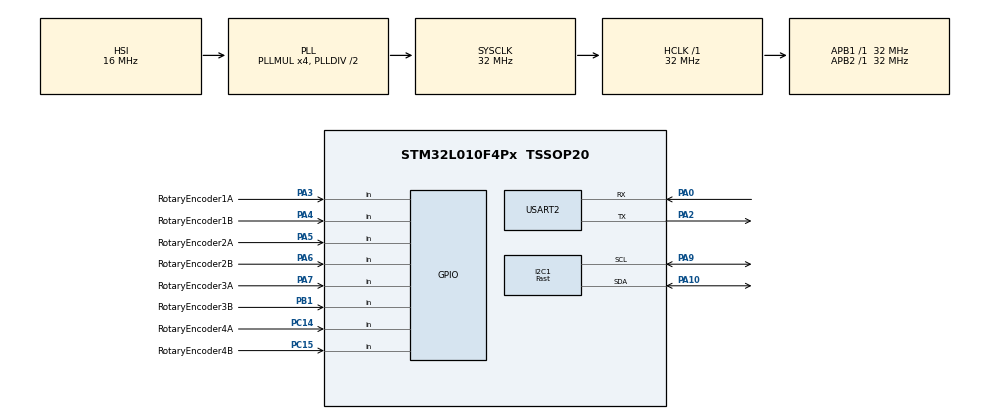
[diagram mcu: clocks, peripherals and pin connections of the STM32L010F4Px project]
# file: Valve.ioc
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Dma.Request0=USART2_RX
Dma.USART2_RX.0.Direction=DMA_PERIPH_TO_MEMORY
Dma.USART2_RX.0.Instance=DMA1_Channel3
Dma.USART2_RX.0.MemDataAlignment=DMA_MDATAALIGN_BYTE
Dma.USART2_RX.0.MemInc=DMA_MINC_ENABLE
Dma.USART2_RX.0.Mode=DMA_CIRCULAR
Dma.USART2_RX.0.PeriphDataAlignment=DMA_PDATAALIGN_BYTE
Dma.USART2_RX.0.PeriphInc=DMA_PINC_DISABLE
Dma.USART2_RX.0.Priority=DMA_PRIORITY_LOW
I2C1.I2C_Speed_Mode=I2C_Fast
I2C1.Timing=0x00300F38
Mcu.Family=STM32L0
Mcu.Name=STM32L010F4Px
Mcu.Package=TSSOP20
NVIC.DMA1_Channel2_3_IRQn=true\:0\:0\:false\:false\:true\:false\:true
NVIC.TIM2_IRQn=true\:0\:0\:false\:false\:true\:true\:true
PA0-CK_IN.Mode=Asynchronous
PA0-CK_IN.Signal=USART2_RX
PA10.Mode=I2C
PA10.Signal=I2C1_SDA
PA13.Mode=Serial_Wire
PA13.Signal=SYS_SWDIO
PA14.Mode=Serial_Wire
PA14.Signal=SYS_SWCLK
PA2.Mode=Asynchronous
PA2.Signal=USART2_TX
PA3.GPIO_Label=RotaryEncoder1A
PA3.GPIO_PuPd=GPIO_PULLUP
PA3.Signal=GPIO_Input
PA4.GPIO_Label=RotaryEncoder1B
PA4.GPIO_PuPd=GPIO_PULLUP
PA4.Signal=GPIO_Input
PA5.GPIO_Label=RotaryEncoder2A
PA5.GPIO_PuPd=GPIO_PULLUP
PA5.Signal=GPIO_Input
PA6.GPIO_Label=RotaryEncoder2B
PA6.GPIO_PuPd=GPIO_PULLUP
PA6.Signal=GPIO_Input
PA7.GPIO_Label=RotaryEncoder3A
PA7.GPIO_PuPd=GPIO_PULLUP
PA7.Signal=GPIO_Input
PA9.Mode=I2C
PA9.Signal=I2C1_SCL
PB1.GPIO_Label=RotaryEncoder3B
PB1.GPIO_PuPd=GPIO_PULLUP
PB1.Signal=GPIO_Input
PC14-OSC32_IN.GPIO_Label=RotaryEncoder4A
PC14-OSC32_IN.GPIO_PuPd=GPIO_PULLUP
PC14-OSC32_IN.Signal=GPIO_Input
PC15-OSC32_OUT.GPIO_Label=RotaryEncoder4B
PC15-OSC32_OUT.GPIO_PuPd=GPIO_PULLUP
PC15-OSC32_OUT.Signal=GPIO_Input
ProjectManager.HeapSize=0x200
ProjectManager.StackSize=0x200
ProjectManager.TargetToolchain=MDK-ARM V5.27
RCC.AHBFreq_Value=32000000
RCC.APB1Freq_Value=32000000
RCC.APB1TimFreq_Value=32000000
RCC.APB2Freq_Value=32000000
RCC.APB2TimFreq_Value=32000000
RCC.HCLKFreq_Value=32000000
RCC.HSE_VALUE=8000000
RCC.HSI16_VALUE=16000000
RCC.HSI_VALUE=16000000
RCC.LSE_VALUE=32768
RCC.MSI_VALUE=2097000
RCC.PLLMUL=RCC_PLLMUL_4
RCC.SYSCLKFreq_VALUE=32000000
RCC.SYSCLKSource=RCC_SYSCLKSOURCE_PLLCLK
RCC.VCOOutputFreq_Value=64000000
TIM2.AutoReloadPreload=TIM_AUTORELOAD_PRELOAD_ENABLE
TIM2.ClockDivision=TIM_CLOCKDIVISION_DIV1
TIM2.Period=36000-1
USART2.VirtualMode=VM_ASYNC
VP_TIM2_VS_ClockSourceINT.Mode=Internal
board=custom

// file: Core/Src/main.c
/* USER CODE BEGIN Header */
/**
  ******************************************************************************
  * @file           : main.c
  * @brief          : Main program body
  ******************************************************************************
  * @attention
  *
  * <h2><center>&copy; Copyright (c) 2021 STMicroelectronics.
  * All rights reserved.</center></h2>
  *
  * This software component is licensed by ST under BSD 3-Clause license,
  * the "License"; You may not use this file except in compliance with the
  * License. You may obtain a copy of the License at:
  *                        opensource.org/licenses/BSD-3-Clause
  *
  ******************************************************************************
  */
/* USER CODE END Header */
#include "main.h"

/* USER CODE BEGIN Includes */
#include "ValveMain.h"
/* USER CODE END Includes */

I2C_HandleTypeDef hi2c1;

TIM_HandleTypeDef htim2;

UART_HandleTypeDef huart2;
DMA_HandleTypeDef hdma_usart2_rx;

void SystemClock_Config(void);
static void MX_GPIO_Init(void);
static void MX_DMA_Init(void);
static void MX_USART2_UART_Init(void);
static void MX_TIM2_Init(void);
static void MX_I2C1_Init(void);

int main(void)
{

  /* MCU Configuration--------------------------------------------------------*/

  /* Reset of all peripherals, Initializes the Flash interface and the Systick. */
  HAL_Init();

  /* Configure the system clock */
  SystemClock_Config();

  /* Initialize all configured peripherals */
  MX_GPIO_Init();
  MX_DMA_Init();
  MX_USART2_UART_Init();
  MX_TIM2_Init();
  MX_I2C1_Init();

  /* Infinite loop */
  /* USER CODE BEGIN WHILE */
	ValveMain();
  while (1)
  {
    /* USER CODE END WHILE */

  }
}

void SystemClock_Config(void)
{
  RCC_OscInitTypeDef RCC_OscInitStruct = {0};
  RCC_ClkInitTypeDef RCC_ClkInitStruct = {0};
  RCC_PeriphCLKInitTypeDef PeriphClkInit = {0};

  /** Configure the main internal regulator output voltage
  */
  __HAL_PWR_VOLTAGESCALING_CONFIG(PWR_REGULATOR_VOLTAGE_SCALE1);
  /** Initializes the RCC Oscillators according to the specified parameters
  * in the RCC_OscInitTypeDef structure.
  */
  RCC_OscInitStruct.OscillatorType = RCC_OSCILLATORTYPE_HSI;
  RCC_OscInitStruct.HSIState = RCC_HSI_ON;
  RCC_OscInitStruct.HSICalibrationValue = RCC_HSICALIBRATION_DEFAULT;
  RCC_OscInitStruct.PLL.PLLState = RCC_PLL_ON;
  RCC_OscInitStruct.PLL.PLLSource = RCC_PLLSOURCE_HSI;
  RCC_OscInitStruct.PLL.PLLMUL = RCC_PLLMUL_4;
  RCC_OscInitStruct.PLL.PLLDIV = RCC_PLLDIV_2;
  if (HAL_RCC_OscConfig(&RCC_OscInitStruct) != HAL_OK)
  {
    Error_Handler();
  }
  /** Initializes the CPU, AHB and APB buses clocks
  */
  RCC_ClkInitStruct.ClockType = RCC_CLOCKTYPE_HCLK|RCC_CLOCKTYPE_SYSCLK
                              |RCC_CLOCKTYPE_PCLK1|RCC_CLOCKTYPE_PCLK2;
  RCC_ClkInitStruct.SYSCLKSource = RCC_SYSCLKSOURCE_PLLCLK;
  RCC_ClkInitStruct.AHBCLKDivider = RCC_SYSCLK_DIV1;
  RCC_ClkInitStruct.APB1CLKDivider = RCC_HCLK_DIV1;
  RCC_ClkInitStruct.APB2CLKDivider = RCC_HCLK_DIV1;

  if (HAL_RCC_ClockConfig(&RCC_ClkInitStruct, FLASH_LATENCY_1) != HAL_OK)
  {
    Error_Handler();
  }
  PeriphClkInit.PeriphClockSelection = RCC_PERIPHCLK_USART2|RCC_PERIPHCLK_I2C1;
  PeriphClkInit.Usart2ClockSelection = RCC_USART2CLKSOURCE_PCLK1;
  PeriphClkInit.I2c1ClockSelection = RCC_I2C1CLKSOURCE_PCLK1;
  if (HAL_RCCEx_PeriphCLKConfig(&PeriphClkInit) != HAL_OK)
  {
    Error_Handler();
  }
}

static void MX_I2C1_Init(void)
{

  hi2c1.Instance = I2C1;
  hi2c1.Init.Timing = 0x00300F38;
  hi2c1.Init.OwnAddress1 = 0;
  hi2c1.Init.AddressingMode = I2C_ADDRESSINGMODE_7BIT;
  hi2c1.Init.DualAddressMode = I2C_DUALADDRESS_DISABLE;
  hi2c1.Init.OwnAddress2 = 0;
  hi2c1.Init.OwnAddress2Masks = I2C_OA2_NOMASK;
  hi2c1.Init.GeneralCallMode = I2C_GENERALCALL_DISABLE;
  hi2c1.Init.NoStretchMode = I2C_NOSTRETCH_DISABLE;
  if (HAL_I2C_Init(&hi2c1) != HAL_OK)
  {
    Error_Handler();
  }
  /** Configure Analogue filter
  */
  if (HAL_I2CEx_ConfigAnalogFilter(&hi2c1, I2C_ANALOGFILTER_ENABLE) != HAL_OK)
  {
    Error_Handler();
  }
  /** Configure Digital filter
  */
  if (HAL_I2CEx_ConfigDigitalFilter(&hi2c1, 0) != HAL_OK)
  {
    Error_Handler();
  }

}

static void MX_TIM2_Init(void)
{

  TIM_ClockConfigTypeDef sClockSourceConfig = {0};
  TIM_MasterConfigTypeDef sMasterConfig = {0};

  htim2.Instance = TIM2;
  htim2.Init.Prescaler = 0;
  htim2.Init.CounterMode = TIM_COUNTERMODE_UP;
  htim2.Init.Period = 36000-1;
  htim2.Init.ClockDivision = TIM_CLOCKDIVISION_DIV1;
  htim2.Init.AutoReloadPreload = TIM_AUTORELOAD_PRELOAD_ENABLE;
  if (HAL_TIM_Base_Init(&htim2) != HAL_OK)
  {
    Error_Handler();
  }
  sClockSourceConfig.ClockSource = TIM_CLOCKSOURCE_INTERNAL;
  if (HAL_TIM_ConfigClockSource(&htim2, &sClockSourceConfig) != HAL_OK)
  {
    Error_Handler();
  }
  sMasterConfig.MasterOutputTrigger = TIM_TRGO_RESET;
  sMasterConfig.MasterSlaveMode = TIM_MASTERSLAVEMODE_DISABLE;
  if (HAL_TIMEx_MasterConfigSynchronization(&htim2, &sMasterConfig) != HAL_OK)
  {
    Error_Handler();
  }

}

static void MX_USART2_UART_Init(void)
{

  huart2.Instance = USART2;
  huart2.Init.BaudRate = 115200;
  huart2.Init.WordLength = UART_WORDLENGTH_8B;
  huart2.Init.StopBits = UART_STOPBITS_1;
  huart2.Init.Parity = UART_PARITY_NONE;
  huart2.Init.Mode = UART_MODE_TX_RX;
  huart2.Init.HwFlowCtl = UART_HWCONTROL_NONE;
  huart2.Init.OverSampling = UART_OVERSAMPLING_16;
  huart2.Init.OneBitSampling = UART_ONE_BIT_SAMPLE_DISABLE;
  huart2.AdvancedInit.AdvFeatureInit = UART_ADVFEATURE_NO_INIT;
  if (HAL_UART_Init(&huart2) != HAL_OK)
  {
    Error_Handler();
  }

}

static void MX_DMA_Init(void)
{

  /* DMA controller clock enable */
  __HAL_RCC_DMA1_CLK_ENABLE();

  /* DMA interrupt init */
  /* DMA1_Channel2_3_IRQn interrupt configuration */
  HAL_NVIC_SetPriority(DMA1_Channel2_3_IRQn, 0, 0);
  HAL_NVIC_EnableIRQ(DMA1_Channel2_3_IRQn);

}

static void MX_GPIO_Init(void)
{
  GPIO_InitTypeDef GPIO_InitStruct = {0};

  /* GPIO Ports Clock Enable */
  __HAL_RCC_GPIOC_CLK_ENABLE();
  __HAL_RCC_GPIOA_CLK_ENABLE();
  __HAL_RCC_GPIOB_CLK_ENABLE();

  /*Configure GPIO pins : RotaryEncoder4A_Pin RotaryEncoder4B_Pin */
  GPIO_InitStruct.Pin = RotaryEncoder4A_Pin|RotaryEncoder4B_Pin;
  GPIO_InitStruct.Mode = GPIO_MODE_INPUT;
  GPIO_InitStruct.Pull = GPIO_PULLUP;
  HAL_GPIO_Init(GPIOC, &GPIO_InitStruct);

  /*Configure GPIO pins : RotaryEncoder1A_Pin RotaryEncoder1B_Pin RotaryEncoder2A_Pin RotaryEncoder2B_Pin
                           RotaryEncoder3A_Pin */
  GPIO_InitStruct.Pin = RotaryEncoder1A_Pin|RotaryEncoder1B_Pin|RotaryEncoder2A_Pin|RotaryEncoder2B_Pin
                          |RotaryEncoder3A_Pin;
  GPIO_InitStruct.Mode = GPIO_MODE_INPUT;
  GPIO_InitStruct.Pull = GPIO_PULLUP;
  HAL_GPIO_Init(GPIOA, &GPIO_InitStruct);

  /*Configure GPIO pin : RotaryEncoder3B_Pin */
  GPIO_InitStruct.Pin = RotaryEncoder3B_Pin;
  GPIO_InitStruct.Mode = GPIO_MODE_INPUT;
  GPIO_InitStruct.Pull = GPIO_PULLUP;
  HAL_GPIO_Init(RotaryEncoder3B_GPIO_Port, &GPIO_InitStruct);

}

void Error_Handler(void)
{
  __disable_irq();
  while (1)
  {
  }
}

/************************ (C) COPYRIGHT STMicroelectronics *****END OF FILE****/
